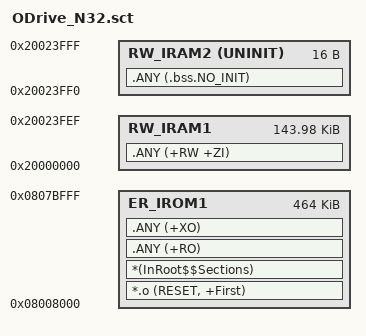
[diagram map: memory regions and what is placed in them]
; *************************************************************
; *** Scatter-Loading Description File generated by uVision ***
; *************************************************************

; The first 32 KB (0x08000000..0x08007FFF) hold the OpenBootloader; the
; application starts at 0x08008000 and its vector table offset
; (VECT_TAB_OFFSET in system_n32h47x_48x.c) must match that origin.
; The top two 8 KB pages (0x0807C000 / 0x0807E000) hold the config records;
; the application region stops before them so the image cannot overlap.
LR_IROM1 0x08008000 0x00074000  {    ; load region size_region
  ER_IROM1 0x08008000 0x00074000  {  ; load address = execution address
   *.o (RESET, +First)
   *(InRoot$$Sections)
   .ANY (+RO)
   .ANY (+XO)
  }
  RW_IRAM1 0x20000000 0x00023FF0  {  ; RW data
   .ANY (+RW +ZI)
  }
  RW_IRAM2 0x20023FF0 UNINIT 0x00000010  {
   .ANY (.bss.NO_INIT)
  }
}

